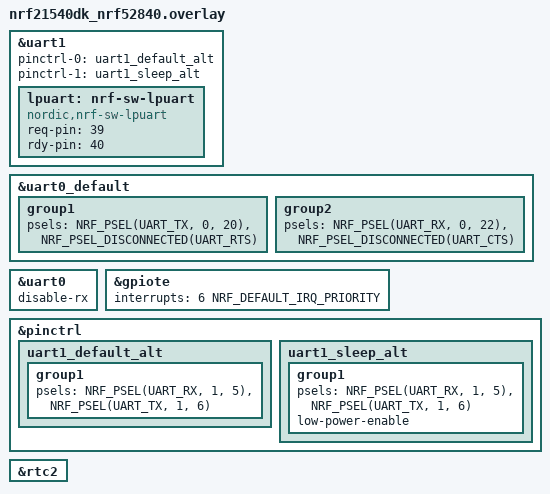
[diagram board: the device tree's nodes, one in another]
/* SPDX-License-Identifier: LicenseRef-Nordic-5-Clause */

&uart1 {
	status = "okay";
	pinctrl-0 = <&uart1_default_alt>;
	pinctrl-1 = <&uart1_sleep_alt>;
	pinctrl-names = "default", "sleep";
	lpuart: nrf-sw-lpuart {
		compatible = "nordic,nrf-sw-lpuart";
		status = "okay";
		req-pin = <39>;
		rdy-pin = <40>;
	};
};

&uart0_default {
	/* Disconnect CTS and RTS lines from pins.
	 * This is a temporary workaround for increased current consumption
	 * observed on nRF21540 v2.0.0 only (~450 uA more than on v1.0.0).
	 */
	group1 {
		psels = <NRF_PSEL(UART_TX, 0, 20)>,
			<NRF_PSEL_DISCONNECTED(UART_RTS)>;
	};
	group2 {
		psels = <NRF_PSEL(UART_RX, 0, 22)>,
			<NRF_PSEL_DISCONNECTED(UART_CTS)>;
	};
};

&uart0 {
	disable-rx;
};

&gpiote {
	interrupts = <6 NRF_DEFAULT_IRQ_PRIORITY>;
};

&pinctrl {
	uart1_default_alt: uart1_default_alt {
		group1 {
			psels = <NRF_PSEL(UART_RX, 1, 5)>,
				<NRF_PSEL(UART_TX, 1, 6)>;
		};
	};

	uart1_sleep_alt: uart1_sleep_alt {
		group1 {
			psels = <NRF_PSEL(UART_RX, 1, 5)>,
				<NRF_PSEL(UART_TX, 1, 6)>;
			low-power-enable;
		};
	};
};

&rtc2 {
	status = "okay";
};
